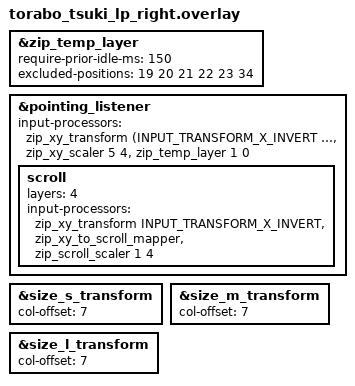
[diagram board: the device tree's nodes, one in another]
#include "torabo_tsuki_lp.dtsi"
#include <input/processors.dtsi>
#include <dt-bindings/zmk/input_transform.h>

&zip_temp_layer {
    require-prior-idle-ms = <150>;
    excluded-positions = <19 20 21 22 23 34>;
};

&pointing_listener {
    input-processors =
        <&zip_xy_transform (INPUT_TRANSFORM_X_INVERT | INPUT_TRANSFORM_Y_INVERT)>,
        <&zip_xy_scaler 5 4>,
        <&zip_temp_layer 1 0>;

    scroll {
        layers = <4>;
        input-processors =
            <&zip_xy_transform INPUT_TRANSFORM_X_INVERT>,
            <&zip_xy_to_scroll_mapper>,
            <&zip_scroll_scaler 1 4>;
    };
};

&size_s_transform {
    col-offset = <7>;
};

&size_m_transform {
    col-offset = <7>;
};

&size_l_transform {
    col-offset = <7>;
};
